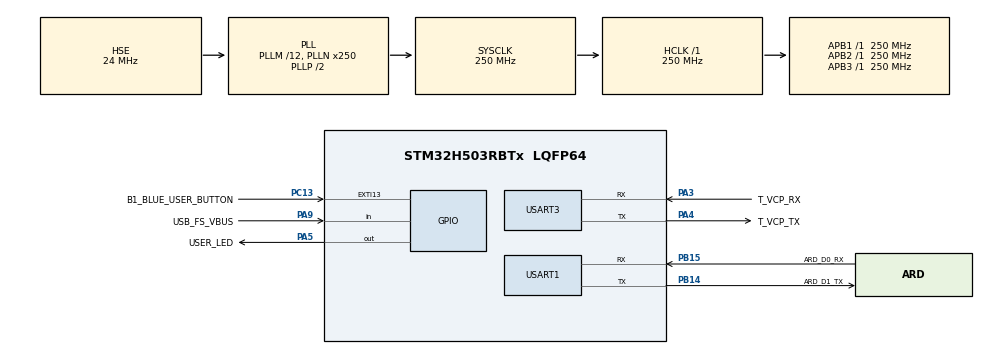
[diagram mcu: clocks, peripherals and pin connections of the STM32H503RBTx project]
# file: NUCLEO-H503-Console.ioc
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BOOTPATH.BootPathName=LEGACY
BOOTPATH.UserSelectedBootPath=LEGACY
Mcu.Family=STM32H5
Mcu.Name=STM32H503RBTx
Mcu.Package=LQFP64
NVIC.PriorityGroup=NVIC_PRIORITYGROUP_4
PA3.GPIO_Label=T_VCP_RX
PA3.Mode=Asynchronous
PA3.Signal=USART3_RX
PA4.GPIO_Label=T_VCP_TX
PA4.Mode=Asynchronous
PA4.Signal=USART3_TX
PA5.GPIO_Label=USER_LED
PA5.Signal=GPIO_Output
PA9.GPIO_Label=USB_FS_VBUS
PA9.Signal=GPIO_Input
PB14.GPIO_Label=ARD_D1_TX
PB14.Mode=Asynchronous
PB14.Signal=USART1_TX
PB15.GPIO_Label=ARD_D0_RX
PB15.Mode=Asynchronous
PB15.Signal=USART1_RX
PC13.GPIO_Label=B1_BLUE_USER_BUTTON
PC13.Signal=GPXTI13
PC14-OSC32_IN(OSC32_IN).Mode=LSE-External-Oscillator
PC14-OSC32_IN(OSC32_IN).Signal=RCC_OSC32_IN
PC15-OSC32_OUT(OSC32_OUT).Mode=LSE-External-Oscillator
PC15-OSC32_OUT(OSC32_OUT).Signal=RCC_OSC32_OUT
PH0-OSC_IN(PH0).Mode=HSE-External-Oscillator
PH0-OSC_IN(PH0).Signal=RCC_OSC_IN
PH1-OSC_OUT(PH1).Mode=HSE-External-Oscillator
PH1-OSC_OUT(PH1).Signal=RCC_OSC_OUT
ProjectManager.HeapSize=0x200
ProjectManager.StackSize=0x400
ProjectManager.TargetToolchain=STM32CubeIDE
RCC.ADCFreq_Value=250000000
RCC.AHBFreq_Value=250000000
RCC.APB1Freq_Value=250000000
RCC.APB1TimFreq_Value=250000000
RCC.APB2Freq_Value=250000000
RCC.APB2TimFreq_Value=250000000
RCC.APB3Freq_Value=250000000
RCC.CSI_VALUE=4000000
RCC.CortexFreq_Value=250000000
RCC.EPOD_VALUE=24000000
RCC.HCLKFreq_Value=250000000
RCC.HSE_VALUE=24000000
RCC.HSI48_VALUE=48000000
RCC.HSIDiv=RCC_HSI_DIV1
RCC.HSI_VALUE=64000000
RCC.LSIRC_VALUE=32000
RCC.PLLM=12
RCC.PLLN=250
RCC.PLLSourceVirtual=RCC_PLL1_SOURCE_HSE
RCC.SYSCLKFreq_VALUE=250000000
RCC.SYSCLKSource=RCC_SYSCLKSOURCE_PLLCLK
RCC.USBFreq_Value=48000000
RCC.VCOOutputFreq_Value=500000000
USART1.VirtualMode=VM_ASYNC
USART3.FIFOMode=FIFOMODE_DISABLE
USART3.VirtualMode=VM_ASYNC
VP_BOOTPATH_VS_BOOTPATH.Mode=BP_Activate
VP_CORTEX_M33_NS_VS_Ext.Mode=External_Mode
VP_ICACHE_VS_ICACHE.Mode=DirectMappedCache
VP_MEMORYMAP_VS_MEMORYMAP.Mode=CurAppReg
VP_PWR_VS_DBSignals.Mode=DisableDeadBatterySignals
VP_PWR_VS_LPOM.Mode=PowerOptimisation
VP_PWR_VS_SECSignals.Mode=Security/Privilege
board=NUCLEO-H503RB

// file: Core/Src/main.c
/* USER CODE BEGIN Header */
/**
  ******************************************************************************
  * @file           : main.c
  * @brief          : Main program body
  ******************************************************************************
  * @attention
  *
  * Copyright (c) 2024 STMicroelectronics.
  * All rights reserved.
  *
  * This software is licensed under terms that can be found in the LICENSE file
  * in the root directory of this software component.
  * If no LICENSE file comes with this software, it is provided AS-IS.
  *
  ******************************************************************************
  */
/* USER CODE END Header */
#include "main.h"

/* USER CODE BEGIN Includes */
#include <stdio.h>
/* USER CODE END Includes */

UART_HandleTypeDef huart1;
UART_HandleTypeDef huart3;

void SystemClock_Config(void);
static void MX_GPIO_Init(void);
static void MX_ICACHE_Init(void);
static void MX_USART1_UART_Init(void);
static void MX_USART3_UART_Init(void);
/* USER CODE BEGIN PFP */
#define PUTCHAR_PROTOTYPE int __io_putchar(int ch)
/* USER CODE END PFP */

int main(void)
{

  /* MCU Configuration--------------------------------------------------------*/

  /* Reset of all peripherals, Initializes the Flash interface and the Systick. */
  HAL_Init();

  /* Configure the system clock */
  SystemClock_Config();

  /* Initialize all configured peripherals */
  MX_GPIO_Init();
  MX_ICACHE_Init();
  MX_USART1_UART_Init();
  MX_USART3_UART_Init();
  /* USER CODE BEGIN 2 */
  int number=1;
  char text[10];
  /* USER CODE END 2 */

  /* Infinite loop */
  /* USER CODE BEGIN WHILE */
  while (1)
  {
	  snprintf (text, 10, "%6d  \n\r", (int)number);//show text with length check
	  printf("%s",text);
	  HAL_GPIO_WritePin(USER_LED_GPIO_Port, USER_LED_Pin, GPIO_PIN_RESET);
	  HAL_Delay(1000);

	  HAL_GPIO_WritePin(USER_LED_GPIO_Port, USER_LED_Pin, GPIO_PIN_SET);
	  HAL_Delay(1000);
	  number++;
    /* USER CODE END WHILE */

  }
}

void SystemClock_Config(void)
{
  RCC_OscInitTypeDef RCC_OscInitStruct = {0};
  RCC_ClkInitTypeDef RCC_ClkInitStruct = {0};

  /** Configure the main internal regulator output voltage
  */
  __HAL_PWR_VOLTAGESCALING_CONFIG(PWR_REGULATOR_VOLTAGE_SCALE0);

  while(!__HAL_PWR_GET_FLAG(PWR_FLAG_VOSRDY)) {}

  /** Initializes the RCC Oscillators according to the specified parameters
  * in the RCC_OscInitTypeDef structure.
  */
  RCC_OscInitStruct.OscillatorType = RCC_OSCILLATORTYPE_HSE;
  RCC_OscInitStruct.HSEState = RCC_HSE_ON;
  RCC_OscInitStruct.PLL.PLLState = RCC_PLL_ON;
  RCC_OscInitStruct.PLL.PLLSource = RCC_PLL1_SOURCE_HSE;
  RCC_OscInitStruct.PLL.PLLM = 12;
  RCC_OscInitStruct.PLL.PLLN = 250;
  RCC_OscInitStruct.PLL.PLLP = 2;
  RCC_OscInitStruct.PLL.PLLQ = 2;
  RCC_OscInitStruct.PLL.PLLR = 2;
  RCC_OscInitStruct.PLL.PLLRGE = RCC_PLL1_VCIRANGE_1;
  RCC_OscInitStruct.PLL.PLLVCOSEL = RCC_PLL1_VCORANGE_WIDE;
  RCC_OscInitStruct.PLL.PLLFRACN = 0;
  if (HAL_RCC_OscConfig(&RCC_OscInitStruct) != HAL_OK)
  {
    Error_Handler();
  }

  /** Initializes the CPU, AHB and APB buses clocks
  */
  RCC_ClkInitStruct.ClockType = RCC_CLOCKTYPE_HCLK|RCC_CLOCKTYPE_SYSCLK
                              |RCC_CLOCKTYPE_PCLK1|RCC_CLOCKTYPE_PCLK2
                              |RCC_CLOCKTYPE_PCLK3;
  RCC_ClkInitStruct.SYSCLKSource = RCC_SYSCLKSOURCE_PLLCLK;
  RCC_ClkInitStruct.AHBCLKDivider = RCC_SYSCLK_DIV1;
  RCC_ClkInitStruct.APB1CLKDivider = RCC_HCLK_DIV1;
  RCC_ClkInitStruct.APB2CLKDivider = RCC_HCLK_DIV1;
  RCC_ClkInitStruct.APB3CLKDivider = RCC_HCLK_DIV1;

  if (HAL_RCC_ClockConfig(&RCC_ClkInitStruct, FLASH_LATENCY_5) != HAL_OK)
  {
    Error_Handler();
  }

   /* Select SysTick source clock */
  HAL_SYSTICK_CLKSourceConfig(SYSTICK_CLKSOURCE_HCLK);

   /* Re-Initialize Tick with new clock source */
  if (HAL_InitTick(TICK_INT_PRIORITY) != HAL_OK)
  {
    Error_Handler();
  }
}

static void MX_ICACHE_Init(void)
{

  /** Enable instruction cache in 1-way (direct mapped cache)
  */
  if (HAL_ICACHE_ConfigAssociativityMode(ICACHE_1WAY) != HAL_OK)
  {
    Error_Handler();
  }
  if (HAL_ICACHE_Enable() != HAL_OK)
  {
    Error_Handler();
  }

}

static void MX_USART1_UART_Init(void)
{

  huart1.Instance = USART1;
  huart1.Init.BaudRate = 115200;
  huart1.Init.WordLength = UART_WORDLENGTH_8B;
  huart1.Init.StopBits = UART_STOPBITS_1;
  huart1.Init.Parity = UART_PARITY_NONE;
  huart1.Init.Mode = UART_MODE_TX_RX;
  huart1.Init.HwFlowCtl = UART_HWCONTROL_NONE;
  huart1.Init.OverSampling = UART_OVERSAMPLING_16;
  huart1.Init.OneBitSampling = UART_ONE_BIT_SAMPLE_DISABLE;
  huart1.Init.ClockPrescaler = UART_PRESCALER_DIV1;
  huart1.AdvancedInit.AdvFeatureInit = UART_ADVFEATURE_NO_INIT;
  if (HAL_UART_Init(&huart1) != HAL_OK)
  {
    Error_Handler();
  }
  if (HAL_UARTEx_SetTxFifoThreshold(&huart1, UART_TXFIFO_THRESHOLD_1_8) != HAL_OK)
  {
    Error_Handler();
  }
  if (HAL_UARTEx_SetRxFifoThreshold(&huart1, UART_RXFIFO_THRESHOLD_1_8) != HAL_OK)
  {
    Error_Handler();
  }
  if (HAL_UARTEx_DisableFifoMode(&huart1) != HAL_OK)
  {
    Error_Handler();
  }

}

static void MX_USART3_UART_Init(void)
{

  huart3.Instance = USART3;
  huart3.Init.BaudRate = 115200;
  huart3.Init.WordLength = UART_WORDLENGTH_8B;
  huart3.Init.StopBits = UART_STOPBITS_1;
  huart3.Init.Parity = UART_PARITY_NONE;
  huart3.Init.Mode = UART_MODE_TX_RX;
  huart3.Init.HwFlowCtl = UART_HWCONTROL_NONE;
  huart3.Init.OverSampling = UART_OVERSAMPLING_16;
  huart3.Init.OneBitSampling = UART_ONE_BIT_SAMPLE_DISABLE;
  huart3.Init.ClockPrescaler = UART_PRESCALER_DIV1;
  huart3.AdvancedInit.AdvFeatureInit = UART_ADVFEATURE_NO_INIT;
  if (HAL_UART_Init(&huart3) != HAL_OK)
  {
    Error_Handler();
  }
  if (HAL_UARTEx_SetTxFifoThreshold(&huart3, UART_TXFIFO_THRESHOLD_1_8) != HAL_OK)
  {
    Error_Handler();
  }
  if (HAL_UARTEx_SetRxFifoThreshold(&huart3, UART_RXFIFO_THRESHOLD_1_8) != HAL_OK)
  {
    Error_Handler();
  }
  if (HAL_UARTEx_DisableFifoMode(&huart3) != HAL_OK)
  {
    Error_Handler();
  }

}

static void MX_GPIO_Init(void)
{
  GPIO_InitTypeDef GPIO_InitStruct = {0};

  /* GPIO Ports Clock Enable */
  __HAL_RCC_GPIOC_CLK_ENABLE();
  __HAL_RCC_GPIOH_CLK_ENABLE();
  __HAL_RCC_GPIOA_CLK_ENABLE();
  __HAL_RCC_GPIOB_CLK_ENABLE();

  /*Configure GPIO pin Output Level */
  HAL_GPIO_WritePin(USER_LED_GPIO_Port, USER_LED_Pin, GPIO_PIN_RESET);

  /*Configure GPIO pin : B1_BLUE_USER_BUTTON_Pin */
  GPIO_InitStruct.Pin = B1_BLUE_USER_BUTTON_Pin;
  GPIO_InitStruct.Mode = GPIO_MODE_IT_RISING;
  GPIO_InitStruct.Pull = GPIO_NOPULL;
  HAL_GPIO_Init(B1_BLUE_USER_BUTTON_GPIO_Port, &GPIO_InitStruct);

  /*Configure GPIO pin : USER_LED_Pin */
  GPIO_InitStruct.Pin = USER_LED_Pin;
  GPIO_InitStruct.Mode = GPIO_MODE_OUTPUT_PP;
  GPIO_InitStruct.Pull = GPIO_NOPULL;
  GPIO_InitStruct.Speed = GPIO_SPEED_FREQ_LOW;
  HAL_GPIO_Init(USER_LED_GPIO_Port, &GPIO_InitStruct);

  /*Configure GPIO pin : USB_FS_VBUS_Pin */
  GPIO_InitStruct.Pin = USB_FS_VBUS_Pin;
  GPIO_InitStruct.Mode = GPIO_MODE_INPUT;
  GPIO_InitStruct.Pull = GPIO_NOPULL;
  HAL_GPIO_Init(USB_FS_VBUS_GPIO_Port, &GPIO_InitStruct);

}

/* USER CODE BEGIN 4 */
/**
  * @brief  Retargets the C library printf function to the USART.
  * @PAram  None
  * @retval None
  */
PUTCHAR_PROTOTYPE
{
  /* Place your implementation of fputc here */
  /* e.g. write a character to the USART1 and Loop until the end of transmission */
  HAL_UART_Transmit(&huart3, (uint8_t *)&ch, 1, 0xFFFF);

  return ch;
}
/* USER CODE END 4 */

void Error_Handler(void)
{
  __disable_irq();
  while (1)
  {
  }
}
